# STM32L4P5 register map
File version: 1.8
CPU: CM4 r0p1, little endian, MPU, FPU, 4 interrupt priority bits
Registers are 32-bit, read-write, reset 0x0 unless marked. A register's access mark holds for its fields unless they carry their own. Offsets are from the block's base; [hi:lo] are bit positions; {n}, {i} and the like mark numbered series; 'fields as' and 'values as' point back to an identical list.

## TIM1 — Advanced-timers
Base 0x40012C00
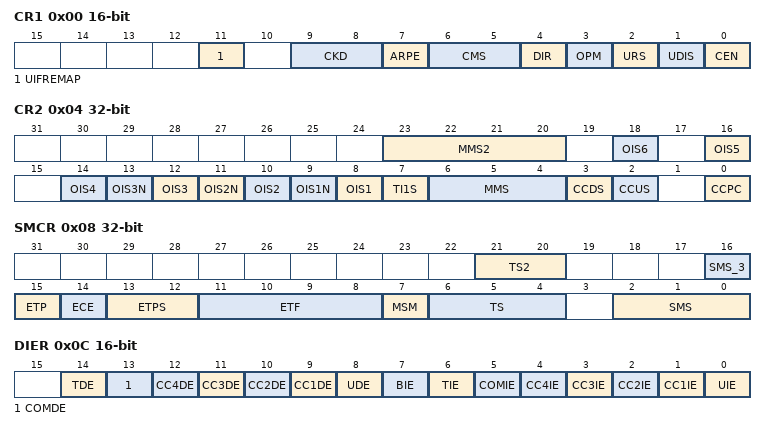
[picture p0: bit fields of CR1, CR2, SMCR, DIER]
0x00 CR1 16-bit — TIM1 control register 1
  [11] UIFREMAP — UIF status bit remapping
    0=Disabled (No remapping. UIF status bit is not copied to TIMx_CNT register bit 31); 1=Enabled (Remapping enabled. UIF status bit is copied to TIMx_CNT register bit 31)
  [9:8] CKD — Clock division This bit-field indicates the division ratio between the timer clock (CK_INT) frequency and the dead-time and sampling clock (t<sub>DTS</sub>)used by the dead-time generators and the digital filters (ETR, TIx): Note: t<sub>DTS</sub> = 1/f<sub>DTS</sub>, t<sub>CK_INT</sub> = 1/f<sub>CK_INT</sub>.
    0=Div1 (t_DTS = t_CK_INT); 1=Div2 (t_DTS = 2 × t_CK_INT); 2=Div4 (t_DTS = 4 × t_CK_INT)
  [7] ARPE — Auto-reload preload enable
    0=Disabled (TIMx_APRR register is not buffered); 1=Enabled (TIMx_APRR register is buffered)
  [6:5] CMS — Center-aligned mode selection Note: Switch from edge-aligned mode to center-aligned mode as long as the counter is enabled (CEN=1) is not allowed
    0=EdgeAligned (The counter counts up or down depending on the direction bit); 1=CenterAligned1 (The counter counts up and down alternatively. Output compare interrupt flags are set only when the counter is counting down.); 2=CenterAligned2 (The counter counts up and down alternatively. Output compare interrupt flags are set only when the counter is counting up.); 3=CenterAligned3 (The counter counts up and down alternatively. Output compare interrupt flags are set both when the counter is counting up or down.)
  [4] DIR — Direction Note: This bit is read only when the timer is configured in Center-aligned mode or Encoder mode.
    0=Up (Counter used as upcounter); 1=Down (Counter used as downcounter)
  [3] OPM — One pulse mode
    0=Disabled (Counter is not stopped at update event); 1=Enabled (Counter stops counting at the next update event (clearing the CEN bit))
  [2] URS — Update request source This bit is set and cleared by software to select the UEV event sources. Counter overflow/underflow Setting the UG bit Update generation through the slave mode controller
    0=AnyEvent (Any of counter overflow/underflow, setting UG, or update through slave mode, generates an update interrupt or DMA request); 1=CounterOnly (Only counter overflow/underflow generates an update interrupt or DMA request)
  [1] UDIS — Update disable This bit is set and cleared by software to enable/disable UEV event generation. Counter overflow/underflow Setting the UG bit Update generation through the slave mode controller Buffered registers are then loaded with their preload values.
    0=Enabled (Update event enabled); 1=Disabled (Update event disabled)
  [0] CEN — Counter enable Note: External clock, gated mode and encoder mode can work only if the CEN bit has been previously set by software. However trigger mode can set the CEN bit automatically by hardware.
    0=Disabled (Counter disabled); 1=Enabled (Counter enabled)
0x04 CR2 — TIM1 control register 2
  [23:20] MMS2 — Master mode selection 2 These bits allow the information to be sent to ADC for synchronization (TRGO2) to be selected. The combination is as follows: Note: The clock of the slave timer or ADC must be enabled prior to receive events from the master timer, and must not be changed on-the-fly while triggers are received from the master timer.
  [2n+7] OIS{n}N (n=1..3) — Output Idle state (OC{n}N output)
    0=Reset (OCxN=0 after a dead-time when MOE=0); 1=Set (OCxN=1 after a dead-time when MOE=0)
  [2n+6] OIS{n} (n=1..6) — Output Idle state (OC{n} output)
    0=Reset (OCx=0 (after a dead-time if OCx(N) is implemented) when MOE=0); 1=Set (OCx=1 (after a dead-time if OCx(N) is implemented) when MOE=0)
  [7] TI1S — TI1 selection
    0=Normal (The TIMx_CH1 pin is connected to TI1 input); 1=XOR (The TIMx_CH1, CH2, CH3 pins are connected to TI1 input)
  [6:4] MMS — Master mode selection These bits allow selected information to be sent in master mode to slave timers for synchronization (TRGO). The combination is as follows: Note: The clock of the slave timer or ADC must be enabled prior to receive events from the master timer, and must not be changed on-the-fly while triggers are received from the master timer.
    0=Reset (The UG bit from the TIMx_EGR register is used as trigger output); 1=Enable (The counter enable signal, CNT_EN, is used as trigger output); 2=Update (The update event is selected as trigger output); 3=ComparePulse (The trigger output send a positive pulse when the CC1IF flag it to be set, as soon as a capture or a compare match occurred); {v}=CompareOC{v-3} (OC{v-3}REF signal is used as trigger output) (v=4..7)
  [3] CCDS — Capture/compare DMA selection
    0=OnCompare (CCx DMA request sent when CCx event occurs); 1=OnUpdate (CCx DMA request sent when update event occurs)
  [2] CCUS — Capture/compare control update selection Note: This bit acts only on channels that have a complementary output.
    0=Sw (When capture/compare control bits are preloaded (CCPC=1), they are updated by setting the COMG bit only); 1=SwOrEdge (When capture/compare control bits are preloaded (CCPC=1), they are updated by setting the COMG bit or when an rising edge occurs on TRGI)
  [0] CCPC — Capture/compare preloaded control Note: This bit acts only on channels that have a complementary output.
    0=NotPreloaded (CCxE, CCxNE and OCxM bits are not preloaded); 1=Preloaded (CCxE, CCxNE and OCxM bits are preloaded)
0x08 SMCR — TIM1 slave mode control register
  [21:20] TS2 — TS[4:3]
  [16] SMS_3
  [15] ETP — External trigger polarity This bit selects whether ETR or ETR is used for trigger operations
    0=NotInverted (ETR is noninverted, active at high level or rising edge); 1=Inverted (ETR is inverted, active at low level or falling edge)
  [14] ECE — External clock enable This bit enables External clock mode 2. Note: Setting the ECE bit has the same effect as selecting external clock mode 1 with TRGI connected to ETRF (SMS=111 and TS=00111). It is possible to simultaneously use external clock mode 2 with the following slave modes: reset mode, gated mode and trigger mode. Nevertheless, TRGI must not be connected to ETRF in this case (TS bits must not be 00111). Note: If external clock mode 1 and external clock mode 2 are enabled at the same time, the external clock input is ETRF.
    0=Disabled (External clock mode 2 disabled); 1=Enabled (External clock mode 2 enabled. The counter is clocked by any active edge on the ETRF signal.)
  [13:12] ETPS — External trigger prescaler External trigger signal ETRP frequency must be at most 1/4 of f<sub>CK_INT</sub> frequency. A prescaler can be enabled to reduce ETRP frequency. It is useful when inputting fast external clocks.
    0=Div1 (Prescaler OFF); 1=Div2 (ETRP frequency divided by 2); 2=Div4 (ETRP frequency divided by 4); 3=Div8 (ETRP frequency divided by 8)
  [11:8] ETF — External trigger filter This bit-field then defines the frequency used to sample ETRP signal and the length of the digital filter applied to ETRP. The digital filter is made of an event counter in which N consecutive events are needed to validate a transition on the output:
    0=No filter, sampling is done at fDTS; 1=FCK_INT_N2 (fSAMPLING=fCK_INT, N=2); 2=FCK_INT_N4 (fSAMPLING=fCK_INT, N=4); 3=FCK_INT_N8 (fSAMPLING=fCK_INT, N=8); 4=FDTS_Div2_N6 (fSAMPLING=fDTS/2, N=6); 5=FDTS_Div2_N8 (fSAMPLING=fDTS/2, N=8); 6=FDTS_Div4_N6 (fSAMPLING=fDTS/4, N=6); 7=FDTS_Div4_N8 (fSAMPLING=fDTS/4, N=8); 8=FDTS_Div8_N6 (fSAMPLING=fDTS/8, N=6); 9=FDTS_Div8_N8 (fSAMPLING=fDTS/8, N=8); 10=FDTS_Div16_N5 (fSAMPLING=fDTS/16, N=5); 11=FDTS_Div16_N6 (fSAMPLING=fDTS/16, N=6); 12=FDTS_Div16_N8 (fSAMPLING=fDTS/16, N=8); 13=FDTS_Div32_N5 (fSAMPLING=fDTS/32, N=5); 14=FDTS_Div32_N6 (fSAMPLING=fDTS/32, N=6); 15=FDTS_Div32_N8 (fSAMPLING=fDTS/32, N=8)
  [7] MSM — Master/slave mode
    0=NoSync (No action); 1=Sync (The effect of an event on the trigger input (TRGI) is delayed to allow a perfect synchronization between the current timer and its slaves (through TRGO). It is useful if we want to synchronize several timers on a single external event.)
  [6:4] TS — TS[0]: Trigger selection This bit-field selects the trigger input to be used to synchronize the counter. Others: Reserved See Table 167: TIMxTIM1 internal trigger connection on page 777 for more details on ITRx meaning for each Timer. Note: These bits must be changed only when they are not used (e.g. when SMS=000) to avoid wrong edge detections at the transition.
    0=ITR0 (Internal Trigger 0 (ITR0)); 1=ITR1 (Internal Trigger 1 (ITR1)); 2=ITR2 (Internal Trigger 2 (ITR2)); 4=TI1F_ED (TI1 Edge Detector (TI1F_ED)); 5=TI1FP1 (Filtered Timer Input 1 (TI1FP1)); 6=TI2FP2 (Filtered Timer Input 2 (TI2FP2)); 7=ETRF (External Trigger input (ETRF))
  [2:0] SMS — SMS[0]: Slave mode selection When external signals are selected the active edge of the trigger signal (TRGI) is linked to the polarity selected on the external input (see Input Control register and Control Register description. Codes above 1000: Reserved. Note: The gated mode must not be used if TI1F_ED is selected as the trigger input (TS=00100). Indeed, TI1F_ED outputs 1 pulse for each transition on TI1F, whereas the gated mode checks the level of the trigger signal. Note: The clock of the slave peripherals (timer, ADC, ...) receiving the TRGO or the TRGO2 signals must be enabled prior to receive events from the master timer, and the clock frequency (prescaler) must not be changed on-the-fly while triggers are received from the master timer.
    0=Disabled (Slave mode disabled - if CEN = ‘1 then the prescaler is clocked directly by the internal clock.); 1=Encoder mode 1 - Counter counts up/down on TI2FP1 edge depending on TI1FP2 level; 2=Encoder mode 2 - Counter counts up/down on TI1FP2 edge depending on TI2FP1 level; 3=Encoder mode 3 - Counter counts up/down on both TI1FP1 and TI2FP2 edges depending on the level of the other input; 4=Reset Mode - Rising edge of the selected trigger input (TRGI) reinitializes the counter and generates an update of the registers; 5=Gated Mode - The counter clock is enabled when the trigger input (TRGI) is high. The counter stops (but is not reset) as soon as the trigger becomes low. Both start and stop of the counter are controlled.; 6=Trigger Mode - The counter starts at a rising edge of the trigger TRGI (but it is not reset). Only the start of the counter is controlled.; 7=Ext_Clock_Mode (External Clock Mode 1 - Rising edges of the selected trigger (TRGI) clock the counter.)
0x0C DIER 16-bit — TIM1 DMA/interrupt enable register
  [14] TDE — Trigger DMA request enable
    0=Disabled (Trigger DMA request disabled); 1=Enabled (Trigger DMA request enabled)
  [13] COMDE — COM DMA request enable
    0=Disabled (COM DMA request disabled); 1=Enabled (COM DMA request enabled)
  [n+8] CC{n}DE (n=1..4) — Capture/Compare {n} DMA request enable
    0=Disabled (CCx DMA request disabled); 1=Enabled (CCx DMA request enabled)
  [8] UDE — Update DMA request enable
    0=Disabled (Update DMA request disabled); 1=Enabled (Update DMA request enabled)
  [7] BIE — Break interrupt enable
    0=Disabled (Break interrupt disabled); 1=Enabled (Break interrupt enabled)
  [6] TIE — Trigger interrupt enable
    0=Disabled (Trigger interrupt disabled); 1=Enabled (Trigger interrupt enabled)
  [5] COMIE — COM interrupt enable
    0=Disabled (COM interrupt disabled); 1=Enabled (COM interrupt enabled)
  [n] CC{n}IE (n=1..4) — Capture/Compare {n} interrupt enable
    0=Disabled (CCx interrupt disabled); 1=Enabled (CCx interrupt enabled)
  [0] UIE — Update interrupt enable
    0=Disabled (Update interrupt disabled); 1=Enabled (Update interrupt enabled)
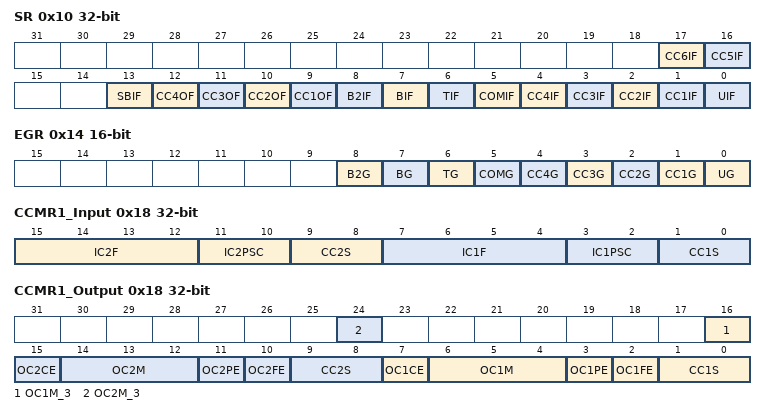
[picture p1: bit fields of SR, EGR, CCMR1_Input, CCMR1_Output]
0x10 SR — TIM1 status register
  [17] CC6IF write-0-clears — Compare 6 interrupt flag Refer to CC1IF description (Note: Channel 6 can only be configured as output)
    on read: 0=NoMatch (No campture/compare has been detected); 1=Match (If CC1 is an output: The content of the counter TIMx_CNT matches the content of the TIMx_CCR1 register. If CC1 is an input: The counter value has been captured in TIMx_CCR1 register.) | on write: 0=Clear flag
  [16] CC5IF write-0-clears — Compare 5 interrupt flag Refer to CC1IF description (Note: Channel 5 can only be configured as output)
    values as CC6IF
  [13] SBIF write-0-clears — System Break interrupt flag This flag is set by hardware as soon as the system break input goes active. It can be cleared by software if the system break input is not active. This flag must be reset to re-start PWM operation.
    on read: 0=NoTrigger (No break event occurred); 1=Trigger (An active level has been detected on the system break input. An interrupt is generated if BIE=1 in the TIMx_DIER register) | on write: 0=Clear flag
  [n+8] CC{n}OF (n=1..4) write-0-clears — Capture/Compare {n} overcapture flag
    on read: 0=No overcapture has been detected; 1=Overcapture (The counter value has been captured in TIMx_CCRx register while CCxIF flag was already set) | on write: 0=Clear flag
  [8] B2IF write-0-clears — Break 2 interrupt flag This flag is set by hardware as soon as the break 2 input goes active. It can be cleared by software if the break 2 input is not active.
    on read: 0=NoTrigger (No break event occurred); 1=Trigger (An active level has been detected on the break 2 input. An interrupt is generated if BIE=1 in the TIMx_DIER register) | on write: 0=Clear flag
  [7] BIF write-0-clears — Break interrupt flag This flag is set by hardware as soon as the break input goes active. It can be cleared by software if the break input is not active.
    on read: 0=NoTrigger (No break event occurred); 1=Trigger (An active level has been detected on the break input. An interrupt is generated if BIE=1 in the TIMx_DIER register) | on write: 0=Clear flag
  [6] TIF write-0-clears — Trigger interrupt flag This flag is set by hardware on the TRG trigger event (active edge detected on TRGI input when the slave mode controller is enabled in all modes but gated mode. It is set when the counter starts or stops when gated mode is selected. It is cleared by software.
    on read: 0=No trigger event occurred; 1=Trigger interrupt pending | on write: 0=Clear flag
  [5] COMIF write-0-clears — COM interrupt flag
    on read: 0=No COM event occurred; 1=COM (COM interrupt pending) | on write: 0=Clear flag
  [n] CC{n}IF (n=1..4) write-0-clears — Capture/compare {n} interrupt flag
    values as CC6IF
  [0] UIF write-0-clears — Update interrupt flag This bit is set by hardware on an update event. It is cleared by software. At overflow or underflow regarding the repetition counter value (update if repetition counter = 0) and if the UDIS=0 in the TIMx_CR1 register. When CNT is reinitialized by software using the UG bit in TIMx_EGR register, if URS=0 and UDIS=0 in the TIMx_CR1 register. When CNT is reinitialized by a trigger event (refer to Section 24.4.3: TIMx slave mode control register (TIM1_SMCRTIMx_SMCR)(x = 1, 8)), if URS=0 and UDIS=0 in the TIMx_CR1 register.
    on read: 0=NoUpdateOccurred; 1=UpdatePending (Update interrupt pending) | on write: 0=Clear flag
0x14 EGR 16-bit wo — TIM1 event generation register
  [8] B2G — Break 2 generation This bit is set by software in order to generate an event, it is automatically cleared by hardware.
    1=Trigger (A break 2 event is generated. MOE bit is cleared and B2IF flag is set. Related interrupt can occur if enabled)
  [7] BG — Break generation This bit is set by software in order to generate an event, it is automatically cleared by hardware.
    1=Trigger (A break event is generated. MOE bit is cleared and BIF flag is set. Related interrupt or DMA transfer can occur if enabled)
  [6] TG — Trigger generation This bit is set by software in order to generate an event, it is automatically cleared by hardware.
    1=Trigger (The TIF flag is set in TIMx_SR register. Related interrupt or DMA transfer can occur if enabled.)
  [5] COMG — Capture/Compare control update generation This bit can be set by software, it is automatically cleared by hardware Note: This bit acts only on channels having a complementary output.
    1=Trigger (When CCPC bit is set, it allows CCxE, CCxNE and OCxM bits to be updated)
  [n] CC{n}G (n=1..4) — Capture/compare {n} generation
    1=Trigger (If CC1 is an output: CC1IF flag is set, Corresponding interrupt or DMA request is sent if enabled. If CC1 is an input: The current value of the counter is captured in TIMx_CCR1 register.)
  [0] UG — Update generation This bit can be set by software, it is automatically cleared by hardware.
    1=Update (Re-initializes the timer counter and generates an update of the registers.)
0x18 CCMR1_Input — TIM1 capture/compare mode register 1
  [9:8] CC2S — Capture/Compare 2 selection This bit-field defines the direction of the channel (input/output) as well as the used input. Note: CC2S bits are writable only when the channel is OFF (CC2E = 0 in TIMx_CCER).
    1=TI2 (CC2 channel is configured as input, IC2 is mapped on TI2); 2=TI1 (CC2 channel is configured as input, IC2 is mapped on TI1); 3=TRC (CC2 channel is configured as input, IC2 is mapped on TRC)
  [8n-1:8n-4] IC{n}F (n=1..2) — Input capture {n} filter
    values as SMCR.ETF
  [8n-5:8n-6] IC{n}PSC (n=1..2) — Input capture {n} prescaler
    0=No prescaler, capture is done each time an edge is detected on the capture input; 1=TwoEvents (Capture is done once every 2 events); 2=FourEvents (Capture is done once every 4 events); 3=EightEvents (Capture is done once every 8 events)
  [1:0] CC1S — Capture/Compare 1 Selection This bit-field defines the direction of the channel (input/output) as well as the used input. Note: CC1S bits are writable only when the channel is OFF (CC1E = 0 in TIMx_CCER).
    1=TI1 (CC1 channel is configured as input, IC1 is mapped on TI1); 2=TI2 (CC1 channel is configured as input, IC1 is mapped on TI2); 3=TRC (CC1 channel is configured as input, IC1 is mapped on TRC)
0x18 CCMR1_Output (alternate view of CCMR1_Input) — TIM1 capture/compare mode register 1
  [8n+8] OC{n}M_3 (n=1..2) — Output compare {n} mode, bit 3
    0=Normal output compare mode (modes 0-7); 1=Extended output compare mode (modes 7-15)
  [8n-1] OC{n}CE (n=1..2) — Output compare {n} clear enable
    0=Disabled (OCxRef is not affected by the ETRF signal); 1=Enabled (OCxRef is cleared as soon as a High level is detected on ETRF signal)
  [8n-2:8n-4] OC{n}M (n=1..2) — Output compare {n} mode
    0=Frozen (The comparison between the output compare register TIMx_CCRy and the counter TIMx_CNT has no effect on the outputs / OpmMode1: Retriggerable OPM mode 1 - In up-counting mode, the channel is active until a trigger event is detected (on TRGI signal). In down-counting mode, the channel is inactive); 1=ActiveOnMatch (Set channel to active level on match. OCyREF signal is forced high when the counter matches the capture/compare register / OpmMode2: Inversely to OpmMode1); 2=InactiveOnMatch (Set channel to inactive level on match. OCyREF signal is forced low when the counter matches the capture/compare register / Reserved); 3=Toggle (OCyREF toggles when TIMx_CNT=TIMx_CCRy / Reserved); 4=ForceInactive (OCyREF is forced low / CombinedPwmMode1: OCyREF has the same behavior as in PWM mode 1. OCyREFC is the logical OR between OC1REF and OC2REF); 5=ForceActive (OCyREF is forced high / CombinedPwmMode2: OCyREF has the same behavior as in PWM mode 2. OCyREFC is the logical AND between OC1REF and OC2REF); 6=PwmMode1 (In upcounting, channel is active as long as TIMx_CNT<TIMx_CCRy else inactive. In downcounting, channel is inactive as long as TIMx_CNT>TIMx_CCRy else active / AsymmetricPwmMode1: OCyREF has the same behavior as in PWM mode 1. OCyREFC outputs OC1REF when the counter is counting up, OC2REF when it is counting down); 7=PwmMode2 (Inversely to PwmMode1 / AsymmetricPwmMode2: Inversely to AsymmetricPwmMode1)
  [8n-5] OC{n}PE (n=1..2) — Output compare {n} preload enable
    0=Disabled (Preload register on CCRx disabled. New values written to CCRx are taken into account immediately); 1=Enabled (Preload register on CCRx enabled. Preload value is loaded into active register on each update event)
  [8n-6] OC{n}FE (n=1..2) — Output compare {n} fast enable
    0=Disabled (Fast output disabled); 1=Enabled (Fast output enabled)
  [8n-7:8n-8] CC{n}S (n=1..2) — Capture/Compare {n} selection
    0=Output (CCx channel is configured as output)
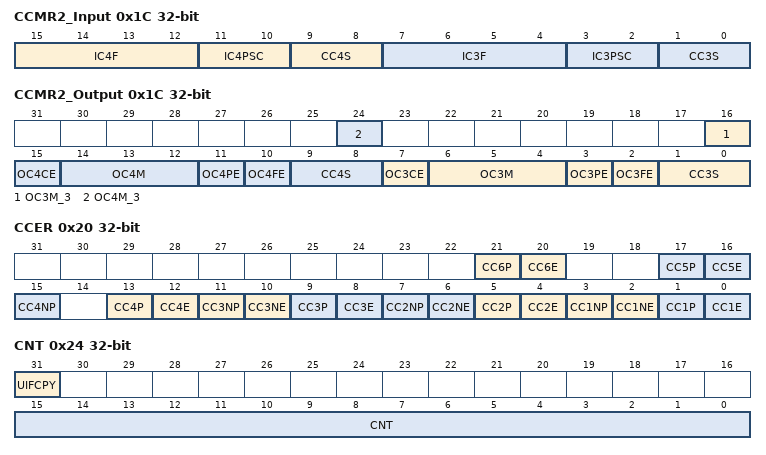
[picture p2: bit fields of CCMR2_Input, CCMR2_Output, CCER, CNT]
0x1C CCMR2_Input — TIM1 capture/compare mode register 2
  [9:8] CC4S — Capture/Compare 4 selection This bit-field defines the direction of the channel (input/output) as well as the used input. Note: CC4S bits are writable only when the channel is OFF (CC4E = 0 in TIMx_CCER).
    1=TI4 (CC4 channel is configured as input, IC4 is mapped on TI4); 2=TI3 (CC4 channel is configured as input, IC4 is mapped on TI3); 3=TRC (CC4 channel is configured as input, IC4 is mapped on TRC)
  [8n-17:8n-20] IC{n}F (n=3..4) — Input capture {n} filter
    values as SMCR.ETF
  [8n-21:8n-22] IC{n}PSC (n=3..4) — Input capture {n} prescaler
    values as CCMR1_Input.IC1PSC
  [1:0] CC3S — Capture/compare 3 selection This bit-field defines the direction of the channel (input/output) as well as the used input. Note: CC3S bits are writable only when the channel is OFF (CC3E = 0 in TIMx_CCER).
    1=TI3 (CC3 channel is configured as input, IC3 is mapped on TI3); 2=TI4 (CC3 channel is configured as input, IC3 is mapped on TI4); 3=TRC (CC3 channel is configured as input, IC3 is mapped on TRC)
0x1C CCMR2_Output (alternate view of CCMR2_Input) — TIM1 capture/compare mode register 2
  [8n-8] OC{n}M_3 (n=3..4) — Output compare {n} mode, bit 3
    values as CCMR1_Output.OC1M_3
  [8n-17] OC{n}CE (n=3..4) — Output compare {n} clear enable
    values as CCMR1_Output.OC1CE
  [8n-18:8n-20] OC{n}M (n=3..4) — Output compare {n} mode
    values as CCMR1_Output.OC1M
  [8n-21] OC{n}PE (n=3..4) — Output compare {n} preload enable
    values as CCMR1_Output.OC1PE
  [8n-22] OC{n}FE (n=3..4) — Output compare {n} fast enable
    values as CCMR1_Output.OC1FE
  [8n-23:8n-24] CC{n}S (n=3..4) — Capture/Compare {n} selection
    0=Output (CCx channel is configured as output)
0x20 CCER — TIM1 capture/compare enable register
  [4n-1] CC{n}NP (n=1..4) — Capture/Compare {n} output Polarity
    0=ActiveHigh (OCxN active high); 1=ActiveLow (OCxN active low)
  [4n-2] CC{n}NE (n=1..3) — Capture/Compare {n} complementary output enable
    0=Disabled (Complementary output disabled); 1=Enabled (Complementary output enabled)
  [4n-3] CC{n}P (n=1..6) — Capture/Compare {n} output Polarity
    0=RisingEdge (Noninverted/rising edge); 1=FallingEdge (Inverted/falling edge)
  [4n-4] CC{n}E (n=1..6) — Capture/Compare {n} output enable
    0=Disabled (Capture disabled); 1=Enabled (Capture enabled)
0x24 CNT access per field — TIM1 counter
  [31] UIFCPY ro — UIF copy This bit is a read-only copy of the UIF bit of the TIMx_ISR register. If the UIFREMAP bit in the TIMxCR1 is reset, bit 31 is reserved and read at 0.
  [15:0] CNT rw — Counter value
0x24 CNT16 16-bit (alternate view of CNT) — 16-bit counter register
  [15:0] CNT — counter value
0x28 PSC 16-bit — TIM1 prescaler
  [15:0] PSC — Prescaler value The counter clock frequency (CK_CNT) is equal to f<sub>CK_PSC</sub> / (PSC[15:0] + 1). PSC contains the value to be loaded in the active prescaler register at each update event (including when the counter is cleared through UG bit of TIMx_EGR register or through trigger controller when configured in reset mode ).
0x2C ARR 16-bit reset 0xFFFF — TIM1 auto-reload register
  [15:0] ARR — Auto-reload value ARR is the value to be loaded in the actual auto-reload register. Refer to the Section 24.3.1: Time-base unit on page 691 for more details about ARR update and behavior. The counter is blocked while the auto-reload value is null.
0x30 RCR 16-bit — TIM1 repetition counter register
  [15:0] REP — Repetition counter value These bits allow the user to set-up the update rate of the compare registers (i.e. periodic transfers from preload to active registers) when preload registers are enable, as well as the update interrupt generation rate, if this interrupt is enable. Each time the REP_CNT related downcounter reaches zero, an update event is generated and it restarts counting from REP value. As REP_CNT is reloaded with REP value only at the repetition update event U_RC, any write to the TIMx_RCR register is not taken in account until the next repetition update event. It means in PWM mode (REP+1) corresponds to: the number of PWM periods in edge-aligned mode the number of half PWM period in center-aligned mode.
{0x30+4i} CCR{i} (i=1..4) 16-bit — capture/compare register
  [15:0] CCR — Capture/Compare value
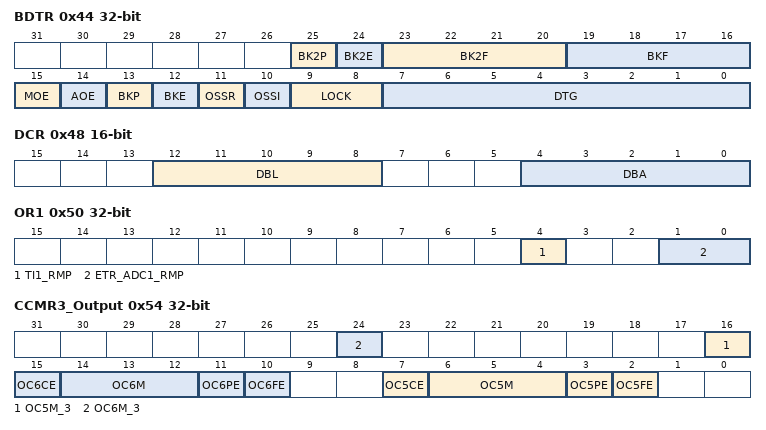
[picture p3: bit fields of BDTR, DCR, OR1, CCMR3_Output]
0x44 BDTR — TIM1 break and dead-time register
  [25] BK2P — Break 2 polarity Note: This bit cannot be modified as long as LOCK level 1 has been programmed (LOCK bits in TIMx_BDTR register). Note: Any write operation to this bit takes a delay of 1 APB clock cycle to become effective.
    0=ActiveLow (Break input BRKx is active low); 1=ActiveHigh (Break input BRKx is active high)
  [24] BK2E — Break 2 enable This bit enables the complete break 2 protection (including all sources connected to bk_acth and BKIN sources, as per Figure 189: Break and Break2 circuitry overview). Note: The BKIN2 must only be used with OSSR = OSSI = 1. Note: This bit cannot be modified when LOCK level 1 has been programmed (LOCK bits in TIMx_BDTR register). Note: Any write operation to this bit takes a delay of 1 APB clock cycle to become effective.
    0=Disabled (Break function x disabled); 1=Enabled (Break function x enabled)
  [23:20] BK2F — Break 2 filter This bit-field defines the frequency used to sample BRK2 input and the length of the digital filter applied to BRK2. The digital filter is made of an event counter in which N consecutive events are needed to validate a transition on the output: Note: This bit cannot be modified when LOCK level 1 has been programmed (LOCK bits in TIMx_BDTR register).
  [19:16] BKF — Break filter This bit-field defines the frequency used to sample BRK input and the length of the digital filter applied to BRK. The digital filter is made of an event counter in which N consecutive events are needed to validate a transition on the output: Note: This bit cannot be modified when LOCK level 1 has been programmed (LOCK bits in TIMx_BDTR register).
  [15] MOE — Main output enable This bit is cleared asynchronously by hardware as soon as one of the break inputs is active (BRK or BRK2). It is set by software or automatically depending on the AOE bit. It is acting only on the channels which are configured in output. In response to a break event or if MOE is written to 0: OC and OCN outputs are disabled or forced to idle state depending on the OSSI bit. See OC/OCN enable description for more details (Section 24.4.11: TIMx capture/compare enable register (TIM1_CCERTIMx_CCER)(x = 1, 8)).
    0=DisabledIdle (OC/OCN are disabled or forced idle depending on OSSI); 1=Enabled (OC/OCN are enabled if CCxE/CCxNE are set)
  [14] AOE — Automatic output enable Note: This bit can not be modified as long as LOCK level 1 has been programmed (LOCK bits in TIMx_BDTR register).
    0=Manual (MOE can be set only by software); 1=Automatic (MOE can be set by software or automatically at the next update event (if none of the break inputs BRK and BRK2 is active))
  [13] BKP — Break polarity Note: This bit can not be modified as long as LOCK level 1 has been programmed (LOCK bits in TIMx_BDTR register). Note: Any write operation to this bit takes a delay of 1 APB clock cycle to become effective.
    values as BK2P
  [12] BKE — Break enable This bit enables the complete break protection (including all sources connected to bk_acth and BKIN sources, as per Figure 189: Break and Break2 circuitry overview). Note: This bit cannot be modified when LOCK level 1 has been programmed (LOCK bits in TIMx_BDTR register). Note: Any write operation to this bit takes a delay of 1 APB clock cycle to become effective.
    values as BK2E
  [11] OSSR — Off-state selection for Run mode This bit is used when MOE=1 on channels having a complementary output which are configured as outputs. OSSR is not implemented if no complementary output is implemented in the timer. See OC/OCN enable description for more details (Section 24.4.11: TIMx capture/compare enable register (TIM1_CCERTIMx_CCER)(x = 1, 8)). Note: This bit can not be modified as soon as the LOCK level 2 has been programmed (LOCK bits in TIMx_BDTR register).
    0=HiZ (When inactive, OC/OCN outputs are disabled); 1=IdleLevel (When inactive, OC/OCN outputs are enabled with their inactive level)
  [10] OSSI — Off-state selection for Idle mode This bit is used when MOE=0 due to a break event or by a software write, on channels configured as outputs. See OC/OCN enable description for more details (Section 24.4.11: TIMx capture/compare enable register (TIM1_CCERTIMx_CCER)(x = 1, 8)). Note: This bit can not be modified as soon as the LOCK level 2 has been programmed (LOCK bits in TIMx_BDTR register).
    0=HiZ (When inactive, OC/OCN outputs are disabled); 1=IdleLevel (When inactive, OC/OCN outputs are forced to idle level)
  [9:8] LOCK — Lock configuration These bits offer a write protection against software errors. Note: The LOCK bits can be written only once after the reset. Once the TIMx_BDTR register has been written, their content is frozen until the next reset.
    0=Off (No bit is write protected); 1=Level1 (Any bits except MOE, OSSR, OSSI and LOCK in TIMx_BDTR register, OISx and OISxN bits in TIMx_CR2 register can no longer be written); 2=Level2 (LOCK Level 1 + CC Polarity bits (CCxP/CCxNP bits in TIMx_CCER register, as long as the related channel is configured in output through the CCxS bits) as well as OSSR and OSSI bits can no longer be written); 3=Level3 (LOCK Level 2 + CC Control bits (OCxM and OCxPE bits in TIMx_CCMRx registers, as long as the related channel is configured in output through the CCxS bits) can no longer be written)
  [7:0] DTG — Dead-time generator setup
0x48 DCR 16-bit — TIM1 DMA control register
  [12:8] DBL range 0..18 — DMA burst length This 5-bit vector defines the length of DMA transfers (the timer recognizes a burst transfer when a read or a write access is done to the TIMx_DMAR address), i.e. the number of transfers. Transfers can be in half-words or in bytes (see example below). ... Example: Let us consider the following transfer: DBL = 7 bytes & DBA = TIMx_CR1. If DBL = 7 bytes and DBA = TIMx_CR1 represents the address of the byte to be transferred, the address of the transfer should be given by the following equation: (TIMx_CR1 address) + DBA + (DMA index), where DMA index = DBL In this example, 7 bytes are added to (TIMx_CR1 address) + DBA, which gives us the address from/to which the data is copied. In this case, the transfer is done to 7 registers starting from the following address: (TIMx_CR1 address) + DBA According to the configuration of the DMA Data Size, several cases may occur: If the DMA Data Size is configured in half-words, 16-bit data is transferred to each of the 7 registers. If the DMA Data Size is configured in bytes, the data is also transferred to 7 registers: the first register contains the first MSB byte, the second register, the first LSB byte and so on. So with the transfer Timer, one also has to specify the size of data transferred by DMA.
  [4:0] DBA — DMA base address This 5-bits vector defines the base-address for DMA transfers (when read/write access are done through the TIMx_DMAR address). DBA is defined as an offset starting from the address of the TIMx_CR1 register. Example: ...
0x4C DMAR — TIM1 DMA address for full transfer
  [31:0] DMAB — DMA register for burst accesses A read or write operation to the DMAR register accesses the register located at the address (TIMx_CR1 address) + (DBA + DMA index) x 4 where TIMx_CR1 address is the address of the control register 1, DBA is the DMA base address configured in TIMx_DCR register, DMA index is automatically controlled by the DMA transfer, and ranges from 0 to DBL (DBL configured in TIMx_DCR).
0x50 OR1 — TIM1 option register 1
  [4] TI1_RMP — Input Capture 1 remap 0: TIM1 input capture 1 is connected to I/O 1: TIM1 input capture 1 is connected to COMP1 output
  [1:0] ETR_ADC1_RMP — External trigger remap on ADC1 analog watchdog 00 : TIM1_ETR is not connected to ADC1 AWDx. This configuration must be selected when the ETR comes from the I/O.
0x54 CCMR3_Output — TIM1 capture/compare mode register 3
  [8n-24] OC{n}M_3 (n=5..6) — Output compare {n} mode, bit 3
    values as CCMR1_Output.OC1M_3
  [8n-33] OC{n}CE (n=5..6) — Output compare {n} clear enable
    values as CCMR1_Output.OC1CE
  [8n-34:8n-36] OC{n}M (n=5..6) — Output compare {n} mode
    values as CCMR1_Output.OC1M
  [8n-37] OC{n}PE (n=5..6) — Output compare {n} preload enable
    values as CCMR1_Output.OC1PE
  [8n-38] OC{n}FE (n=5..6) — Output compare {n} fast enable
    values as CCMR1_Output.OC1FE
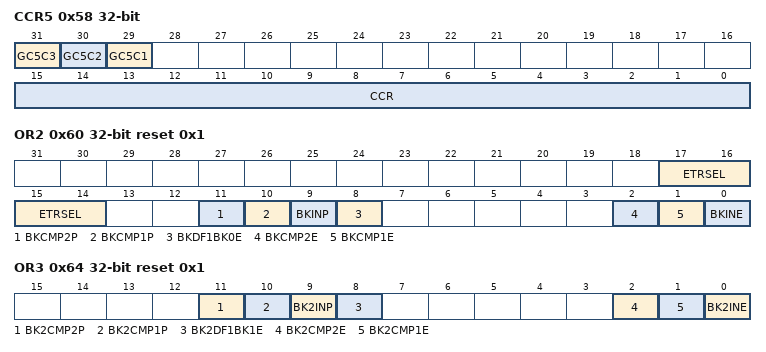
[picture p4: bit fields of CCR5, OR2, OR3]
0x58 CCR5 — capture/compare register
  [31] GC5C3 — Group Channel 5 and Channel 3 Distortion on Channel 3 output: This bit can either have immediate effect or be preloaded and taken into account after an update event (if preload feature is selected in TIMxCCMR2). Note: it is also possible to apply this distortion on combined PWM signals.
  [30] GC5C2 — Group Channel 5 and Channel 2 Distortion on Channel 2 output: This bit can either have immediate effect or be preloaded and taken into account after an update event (if preload feature is selected in TIMxCCMR1). Note: it is also possible to apply this distortion on combined PWM signals.
  [29] GC5C1 — Group Channel 5 and Channel 1 Distortion on Channel 1 output: This bit can either have immediate effect or be preloaded and taken into account after an update event (if preload feature is selected in TIMxCCMR1). Note: it is also possible to apply this distortion on combined PWM signals.
  [15:0] CCR — Capture/Compare value
0x5C CCR6 16-bit — capture/compare register
  [15:0] CCR — Capture/Compare value
0x60 OR2 reset 0x1 — TIM1 option register 2
  [17:14] ETRSEL — ETR source selection These bits select the ETR input source. Others: Reserved Note: These bits can not be modified as long as LOCK level 1 has been programmed (LOCK bits in TIMx_BDTR register).
  [11] BKCMP2P — BRK COMP2 input polarity This bit selects the COMP2 input sensitivity. It must be programmed together with the BKP polarity bit. Note: This bit can not be modified as long as LOCK level 1 has been programmed (LOCK bits in TIMx_BDTR register).
  [10] BKCMP1P — BRK COMP1 input polarity This bit selects the COMP1 input sensitivity. It must be programmed together with the BKP polarity bit. Note: This bit can not be modified as long as LOCK level 1 has been programmed (LOCK bits in TIMx_BDTR register).
  [9] BKINP — BRK BKIN input polarity This bit selects the BKIN alternate function input sensitivity. It must be programmed together with the BKP polarity bit. Note: This bit can not be modified as long as LOCK level 1 has been programmed (LOCK bits in TIMx_BDTR register).
  [8] BKDF1BK0E — BRK dfsdm1_break[0] enable This bit enables the dfsdm1_break[0] for the timer s BRK input. dfsdm1_break[0] output is ORed with the other BRK sources. Note: This bit can not be modified as long as LOCK level 1 has been programmed (LOCK bits in TIMx_BDTR register).
  [2] BKCMP2E — BRK COMP2 enable This bit enables the COMP2 for the timer s BRK input. COMP2 output is ORed with the other BRK sources. Note: This bit can not be modified as long as LOCK level 1 has been programmed (LOCK bits in TIMx_BDTR register).
  [1] BKCMP1E — BRK COMP1 enable This bit enables the COMP1 for the timer s BRK input. COMP1 output is ORed with the other BRK sources. Note: This bit can not be modified as long as LOCK level 1 has been programmed (LOCK bits in TIMx_BDTR register).
  [0] BKINE — BRK BKIN input enable This bit enables the BKIN alternate function input for the timer s BRK input. BKIN input is ORed with the other BRK sources. Note: This bit can not be modified as long as LOCK level 1 has been programmed (LOCK bits in TIMx_BDTR register).
0x64 OR3 reset 0x1 — TIM1 option register 3
  [11] BK2CMP2P — BRK2 COMP2 input polarity This bit selects the COMP2 input sensitivity. It must be programmed together with the BK2P polarity bit. Note: This bit can not be modified as long as LOCK level 1 has been programmed (LOCK bits in TIMx_BDTR register).
  [10] BK2CMP1P — BRK2 COMP1 input polarity This bit selects the COMP1 input sensitivity. It must be programmed together with the BK2P polarity bit. Note: This bit can not be modified as long as LOCK level 1 has been programmed (LOCK bits in TIMx_BDTR register).
  [9] BK2INP — BRK2 BKIN2 input polarity This bit selects the BKIN2 alternate function input sensitivity. It must be programmed together with the BK2P polarity bit. Note: This bit can not be modified as long as LOCK level 1 has been programmed (LOCK bits in TIMx_BDTR register).
  [8] BK2DF1BK1E — BRK2 dfsdm1_break[1] enable This bit enables the dfsdm1_break[1] for the timer s BRK2 input. dfsdm1_break[1] output is ORed with the other BRK2 sources. Note: This bit can not be modified as long as LOCK level 1 has been programmed (LOCK bits in TIMx_BDTR register).
  [2] BK2CMP2E — BRK2 COMP2 enable This bit enables the COMP2 for the timer s BRK2 input. COMP2 output is ORed with the other BRK2 sources. Note: This bit can not be modified as long as LOCK level 1 has been programmed (LOCK bits in TIMx_BDTR register).
  [1] BK2CMP1E — BRK2 COMP1 enable This bit enables the COMP1 for the timer s BRK2 input. COMP1 output is ORed with the other BRK2 sources. Note: This bit can not be modified as long as LOCK level 1 has been programmed (LOCK bits in TIMx_BDTR register).
  [0] BK2INE — BRK2 BKIN input enable This bit enables the BKIN2 alternate function input for the timer s BRK2 input. BKIN2 input is ORed with the other BRK2 sources. Note: This bit can not be modified as long as LOCK level 1 has been programmed (LOCK bits in TIMx_BDTR register).
